# ATtiny1634 device description
Architecture: AVR8; Family: tinyAVR
Programming and debug interfaces: ISP, HVPP, debugWIRE
Registers are 8-bit, access not given, no defined reset value unless marked. A register's access mark holds for its fields unless they carry their own. Offsets are from the block's base; lines under a group give offsets from that group; [hi:lo] are bit positions; {n}, {i} and the like mark numbered series; 'fields as' and 'values as' point back to an identical list; <NAME> marks a mode.

## Ordering variants
standard: 1.8 to 5.5 V

## Memory
prog space: start 0x0000 size 0x4000, little endian
  0x0000 FLASH size 0x4000 flash, rw, executable, page 0x20
signatures space: start 0 size 3, little endian
  0 SIGNATURES size 3 signatures, ro
fuses space: start 0 size 0x0003, little endian
  0 FUSES size 0x0003 fuses, rw
lockbits space: start 0 size 0x0001, little endian
  0 LOCKBITS size 0x0001 lockbits, rw
data space: start 0x0000 size 0x0500, little endian
  0x0000 REGISTERS size 0x0020 regs
  0x0020 MAPPED_IO size 0x00e0 io
  0x0100 IRAM size 0x0400 ram
eeprom space: start 0x0000 size 0x0100, little endian
  0x0000 EEPROM size 0x0100 eeprom, rw, page 0x04
io space: start 0x00 size 0x40, little endian

## Peripheral instances (address, pins/pin function, parameters)
TWI at 0x00 — Two Wire Serial Interface
PORTB at 0x00 — I/O Port
PORTC at 0x00 — I/O Port
PORTA at 0x00 — I/O Port
ADC at 0x00 — Analog-to-Digital Converter
AC at 0x00 — Analog Comparator
EEPROM at 0x00
TC1 at 0x00 — Timer/Counter, 16-bit
TC0 at 0x00 — Timer/Counter, 8-bit
EXINT at 0x00 — External Interrupts
CPU at 0x00 — CPU Registers
USI at 0x00 — Universal Serial Interface
USART0 at 0x00 — USART
USART1 at 0x00 — USART
WDT at 0x00 — Watchdog Timer
FUSE at 0 in fuses — Fuses
LOCKBIT at 0 in lockbits — Lockbits

## Interrupts
0 RESET — External Pin, Power-on Reset, Brown-out Reset and Watchdog Reset
1 INT0 — External Interrupt Request 0
2 PCINT0 — Pin Change Interrupt Request 0
3 PCINT1 — Pin Change Interrupt Request 1
4 PCINT2 — Pin Change Interrupt Request 2
5 WDT — Watchdog Time-out Interrupt
6 TIMER1_CAPT — Timer/Counter1 Capture Event
6 TIM1_CAPT — Timer/Counter1 Capture Event
7 TIMER1_COMPA — Timer/Counter1 Compare Match A
7 TIM1_COMPA — Timer/Counter1 Compare Match A
8 TIMER1_COMPB — Timer/Counter1 Compare Match B
8 TIM1_COMPB — Timer/Counter1 Compare Match B
9 TIMER1_OVF — Timer/Counter1 Overflow
9 TIM1_OVF — Timer/Counter1 Overflow
10 TIMER0_COMPA — TimerCounter0 Compare Match A
10 TIM0_COMPA — TimerCounter0 Compare Match A
11 TIMER0_COMPB — TimerCounter0 Compare Match B
11 TIM0_COMPB — TimerCounter0 Compare Match B
12 TIMER0_OVF — Timer/Couner0 Overflow
12 TIM0_OVF — Timer/Couner0 Overflow
13 ANA_COMP — Analog Comparator
14 ADC — ADC Conversion Complete
14 ADC_READY — ADC Conversion Complete
15 USART0_START
15 USART0_RXS — USART0, Start
16 USART0_RX — USART0, Rx Complete
16 USART0_RXC — USART0, Rx Complete
17 USART0_UDRE — USART0 Data Register Empty
17 USART0_DRE — USART0 Data Register Empty
18 USART0_TX — USART0, Tx Complete
18 USART0_TXC — USART0, Tx Complete
19 USART1_START
19 USART1_RXS — USART1, Start
20 USART1_RX — USART1, Rx Complete
20 USART1_RXC — USART1, Rx Complete
21 USART1_UDRE — USART1 Data Register Empty
21 USART1_DRE — USART1 Data Register Empty
22 USART1_TX — USART1, Tx Complete
22 USART1_TXC — USART1, Tx Complete
23 USI_START — USI Start Condition
23 USI_STR — USI Start Condition
24 USI_OVERFLOW
24 USI_OVF — USI Overflow
25 TWI_SLAVE — Two-wire Serial Interface
25 TWI — Two-wire Serial Interface
26 EE_RDY — EEPROM Ready
27 QTRIP — Touch Sensing

## Properties
SIGNATURES: SIGNATURE0=0x1e, SIGNATURE1=0x94, SIGNATURE2=0x12, JTAGID=0x9412
OCD: OCD_REVISION=1, OCD_DATAREG=0x2e, PROGBASE=0x0000, BUFFERS_PER_FLASH_PAGE=4

## FUSE — Fuses
Instances: FUSE 0 in fuses
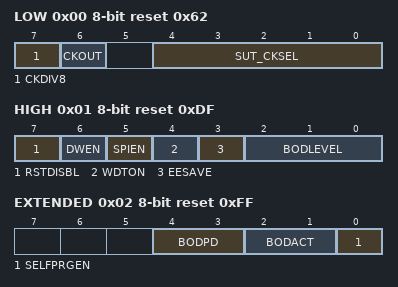
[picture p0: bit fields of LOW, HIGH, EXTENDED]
0x00 LOW reset 0x62
  [7] CKDIV8 — Divide clock by 8 internally
  [6] CKOUT — Clock output on PORTC2
  [4:0] SUT_CKSEL — Select Clock Source
    0=EXTCLK_6CK_16CK_16MS (Ext. Clock; Start-up time PWRDWN/RESET: 6 CK/16 CK + 16 ms); 2=INTRCOSC_8MHZ_6CK_16CK_16MS (Int. RC Osc. 8 MHz; Start-up time PWRDWN/RESET: 6 CK/16 CK + 16 ms); 4=INTULPOSC_32KHZ_6CK_16CK_16MS (Int. ULP Osc. 32 kHz; Start-up time PWRDWN/RESET: 6 CK/16 CK + 16 ms); 8=EXTCRES_0MHZ4_0MHZ9_258CK_16CK_16MS (Ext. Ceramic Res. 0.4-0.9 MHz; Start-up time PWRDWN/RESET: 258 CK/16 CK + 16 ms); 24=EXTCRES_0MHZ4_0MHZ9_1KCK_16CK_16MS (Ext. Ceramic Res. 0.4-0.9 MHz; Start-up time PWRDWN/RESET: 1K CK/16 CK + 16 ms); 9=EXTXOSC_0MHZ4_0MHZ9_16KCK_16CK_16MS (Ext. Crystal Osc. 0.4-0.9 MHz; Start-up time PWRDWN/RESET: 16 K CK/16 CK + 16 ms); 10=EXTCRES_0MHZ9_3MHZ_258CK_16CK_16MS (Ext. Ceramic Res. 0.9-3.0 MHz; Start-up time PWRDWN/RESET: 258 CK/16 CK + 16 ms); 26=EXTCRES_0MHZ9_3MHZ_1KCK_16CK_16MS (Ext. Ceramic Res. 0.9-3.0 MHz; Start-up time PWRDWN/RESET: 1K CK/16 CK + 16 ms); 11=EXTXOSC_0MHZ9_3MHZ_16KCK_16CK_16MS (Ext. Crystal Osc. 0.9-3.0 MHz; Start-up time PWRDWN/RESET: 16 K CK/16 CK + 16 ms); 12=EXTCRES_3MHZ_8MHZ_258CK_16CK_16MS (Ext. Ceramic Res. 3.0-8.0 MHz; Start-up time PWRDWN/RESET: 258 CK/16 CK + 16 ms); 28=EXTCRES_3MHZ_8MHZ_1KCK_16CK_16MS (Ext. Ceramic Res. 3.0-8.0 MHz; Start-up time PWRDWN/RESET: 1K CK/16 CK + 16 ms); 13=EXTXOSC_3MHZ_8MHZ_16KCK_16CK_16MS (Ext. Crystal Osc. 3.0-8.0 MHz; Start-up time PWRDWN/RESET: 16 K CK/16 CK + 16 ms); 14=EXTCRES_8MHZ_XX_258CK_16CK_16MS (Ext. Ceramic Res. 8.0- MHz; Start-up time PWRDWN/RESET: 258 CK/16 CK + 16 ms); 30=EXTCRES_8MHZ_XX_1KCK_16CK_16MS (Ext. Ceramic Res. 8.0- MHz; Start-up time PWRDWN/RESET: 1K CK/16 CK + 16 ms); 15=EXTXOSC_8MHZ_XX_16KCK_16CK_16MS (Ext. Crystal Osc. 8.0- MHz; Start-up time PWRDWN/RESET: 16 K CK/16 CK + 16 ms)
0x01 HIGH reset 0xDF
  [7] RSTDISBL — Reset Disabled (Enable PC2 as i/o pin)
  [6] DWEN — Debug Wire enable
  [5] SPIEN — Serial program downloading (SPI) enabled
  [4] WDTON — Watch-dog Timer always on
  [3] EESAVE — Preserve EEPROM through the Chip Erase cycle
  [2:0] BODLEVEL — Brown-out Detector trigger level
    4=4V3 (Brown-out detection at VCC=4.3 V); 5=2V7 (Brown-out detection at VCC=2.7 V); 6=1V8 (Brown-out detection at VCC=1.8 V)
0x02 EXTENDED reset 0xFF
  [4:3] BODPD — BOD mode of operation when the device is in sleep mode
    1=BOD_SAMPLED (Sampled); 2=BOD_ENABLED (Enabled); 3=BOD_DISABLED (Disabled)
  [2:1] BODACT — BOD mode of operation when the device is active or idle
    values as BODPD
  [0] SELFPRGEN — Self Programming enable
